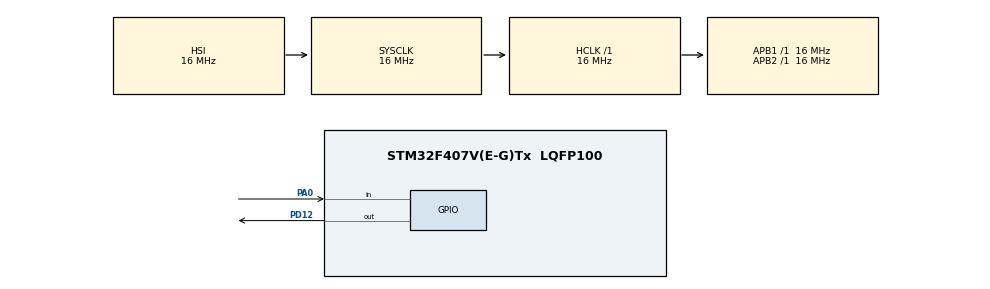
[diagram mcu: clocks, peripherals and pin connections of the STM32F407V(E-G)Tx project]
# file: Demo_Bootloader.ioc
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Mcu.Family=STM32F4
Mcu.Name=STM32F407V(E-G)Tx
Mcu.Package=LQFP100
NVIC.PriorityGroup=NVIC_PRIORITYGROUP_4
PA0-WKUP.Signal=GPIO_Input
PA13.Mode=Serial_Wire
PA13.Signal=SYS_JTMS-SWDIO
PA14.Mode=Serial_Wire
PA14.Signal=SYS_JTCK-SWCLK
PD12.Signal=GPIO_Output
ProjectManager.HeapSize=0x200
ProjectManager.StackSize=0x400
ProjectManager.TargetToolchain=STM32CubeIDE
RCC.AHBFreq_Value=16000000
RCC.APB1Freq_Value=16000000
RCC.APB2Freq_Value=16000000
RCC.CortexFreq_Value=16000000
RCC.HSE_VALUE=25000000
RCC.HSI_VALUE=16000000
RCC.LSE_VALUE=32768
RCC.SYSCLKFreq_VALUE=16000000
RCC.VCOOutputFreq_Value=192000000
board=custom

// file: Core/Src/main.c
/* USER CODE BEGIN Header */
/**
  ******************************************************************************
  * @file           : main.c
  * @brief          : Main program body
  ******************************************************************************
  * @attention
  *
  * Copyright (c) 2022 STMicroelectronics.
  * All rights reserved.
  *
  * This software is licensed under terms that can be found in the LICENSE file
  * in the root directory of this software component.
  * If no LICENSE file comes with this software, it is provided AS-IS.
  *
  ******************************************************************************
  */
/* USER CODE END Header */
#include "main.h"

/* USER CODE BEGIN PD */
#define FLASH_SECTOR2_BASE_ADDRESS 0x08008000U
#define RESET_HANDLER_AT_ADDRESS 0x08008004U
/* USER CODE END PD */

void SystemClock_Config(void);
static void MX_GPIO_Init(void);
/* USER CODE BEGIN PFP */

void jump_to_user_app(void);
void code_for_jump_to_user_app(void);
/* USER CODE END PFP */

int main(void)
{

  /* MCU Configuration--------------------------------------------------------*/

  /* Reset of all peripherals, Initializes the Flash interface and the Systick. */
  HAL_Init();

  /* Configure the system clock */
  SystemClock_Config();

  /* Initialize all configured peripherals */
  MX_GPIO_Init();
  /* USER CODE BEGIN 2 */

  /* Lets check whether button is pressed or not, if not pressed jump to user application */
   if ( HAL_GPIO_ReadPin(GPIOA, GPIO_PIN_0) == GPIO_PIN_SET )
   {

 	  printf("Welcome to Bootloader\n");
 	  //we should continue in bootloader mode

 	  HAL_GPIO_WritePin(GPIOD, GPIO_PIN_12, SET);

   }
   else
   {

 		//jump to user application
 		jump_to_user_app();

   }

  /* USER CODE END 2 */

}

void SystemClock_Config(void)
{
  RCC_OscInitTypeDef RCC_OscInitStruct = {0};
  RCC_ClkInitTypeDef RCC_ClkInitStruct = {0};

  /** Configure the main internal regulator output voltage
  */
  __HAL_RCC_PWR_CLK_ENABLE();
  __HAL_PWR_VOLTAGESCALING_CONFIG(PWR_REGULATOR_VOLTAGE_SCALE1);

  /** Initializes the RCC Oscillators according to the specified parameters
  * in the RCC_OscInitTypeDef structure.
  */
  RCC_OscInitStruct.OscillatorType = RCC_OSCILLATORTYPE_HSI;
  RCC_OscInitStruct.HSIState = RCC_HSI_ON;
  RCC_OscInitStruct.HSICalibrationValue = RCC_HSICALIBRATION_DEFAULT;
  RCC_OscInitStruct.PLL.PLLState = RCC_PLL_NONE;
  if (HAL_RCC_OscConfig(&RCC_OscInitStruct) != HAL_OK)
  {
    Error_Handler();
  }

  /** Initializes the CPU, AHB and APB buses clocks
  */
  RCC_ClkInitStruct.ClockType = RCC_CLOCKTYPE_HCLK|RCC_CLOCKTYPE_SYSCLK
                              |RCC_CLOCKTYPE_PCLK1|RCC_CLOCKTYPE_PCLK2;
  RCC_ClkInitStruct.SYSCLKSource = RCC_SYSCLKSOURCE_HSI;
  RCC_ClkInitStruct.AHBCLKDivider = RCC_SYSCLK_DIV1;
  RCC_ClkInitStruct.APB1CLKDivider = RCC_HCLK_DIV1;
  RCC_ClkInitStruct.APB2CLKDivider = RCC_HCLK_DIV1;

  if (HAL_RCC_ClockConfig(&RCC_ClkInitStruct, FLASH_LATENCY_0) != HAL_OK)
  {
    Error_Handler();
  }
}

static void MX_GPIO_Init(void)
{
  GPIO_InitTypeDef GPIO_InitStruct = {0};

  /* GPIO Ports Clock Enable */
  __HAL_RCC_GPIOA_CLK_ENABLE();
  __HAL_RCC_GPIOD_CLK_ENABLE();

  /*Configure GPIO pin Output Level */
  HAL_GPIO_WritePin(GPIOD, GPIO_PIN_12, GPIO_PIN_RESET);

  /*Configure GPIO pin : PA0 */
  GPIO_InitStruct.Pin = GPIO_PIN_0;
  GPIO_InitStruct.Mode = GPIO_MODE_INPUT;
  GPIO_InitStruct.Pull = GPIO_NOPULL;
  HAL_GPIO_Init(GPIOA, &GPIO_InitStruct);

  /*Configure GPIO pin : PD12 */
  GPIO_InitStruct.Pin = GPIO_PIN_12;
  GPIO_InitStruct.Mode = GPIO_MODE_OUTPUT_PP;
  GPIO_InitStruct.Pull = GPIO_NOPULL;
  GPIO_InitStruct.Speed = GPIO_SPEED_FREQ_LOW;
  HAL_GPIO_Init(GPIOD, &GPIO_InitStruct);

}

/* USER CODE BEGIN 4 */
void jump_to_user_app()
{
	printf("Jump to UserApplication\n");
	code_for_jump_to_user_app();
}

void code_for_jump_to_user_app()
{
	//just a function pointer to hold the address of the reset handler of the user app.
	    void (*app_reset_handler)(void);

	    printf("Jump to UserApplication: Process Begin\n");

	    // 1. configure the MSP by reading the value from the base address of the sector 2
	    uint32_t msp_value = *(volatile uint32_t *)FLASH_SECTOR2_BASE_ADDRESS;
	    printf("Setting Main Stack Pointer:MSP value : %#x\n",msp_value);

	    //This function comes from CMSIS.
	    __set_MSP(msp_value);

	    //SCB->VTOR = FLASH_SECTOR2_BASE_ADDRESS;

	    /* 2. Now fetch the reset handler address of the user application
	     * from the location RESET_HANDLER_AT_ADDRESS=FLASH_SECTOR2_BASE_ADDRESS+4
	     */
	    uint32_t resethandler_address = *(volatile uint32_t *) (RESET_HANDLER_AT_ADDRESS);

	    app_reset_handler = (void*) resethandler_address;

	    //3. jump to reset handler of the user application
	    app_reset_handler();
}
/* USER CODE END 4 */

void Error_Handler(void)
{
  __disable_irq();
  while (1)
  {
  }
}
